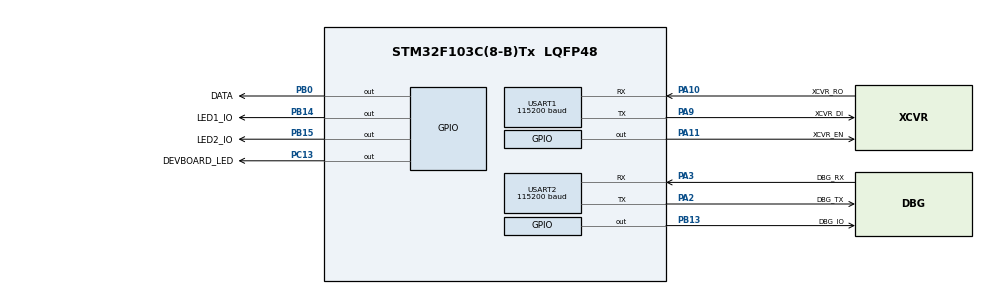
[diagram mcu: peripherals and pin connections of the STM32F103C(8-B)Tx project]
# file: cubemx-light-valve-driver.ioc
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Dma.Request0=USART1_RX
Dma.Request1=USART2_TX
Dma.USART1_RX.0.Direction=DMA_PERIPH_TO_MEMORY
Dma.USART1_RX.0.Instance=DMA1_Channel5
Dma.USART1_RX.0.MemDataAlignment=DMA_MDATAALIGN_BYTE
Dma.USART1_RX.0.MemInc=DMA_MINC_ENABLE
Dma.USART1_RX.0.Mode=DMA_CIRCULAR
Dma.USART1_RX.0.PeriphDataAlignment=DMA_PDATAALIGN_BYTE
Dma.USART1_RX.0.PeriphInc=DMA_PINC_DISABLE
Dma.USART1_RX.0.Priority=DMA_PRIORITY_MEDIUM
Dma.USART2_TX.1.Direction=DMA_MEMORY_TO_PERIPH
Dma.USART2_TX.1.Instance=DMA1_Channel7
Dma.USART2_TX.1.MemDataAlignment=DMA_MDATAALIGN_BYTE
Dma.USART2_TX.1.MemInc=DMA_MINC_ENABLE
Dma.USART2_TX.1.Mode=DMA_NORMAL
Dma.USART2_TX.1.PeriphDataAlignment=DMA_PDATAALIGN_BYTE
Dma.USART2_TX.1.PeriphInc=DMA_PINC_DISABLE
Dma.USART2_TX.1.Priority=DMA_PRIORITY_LOW
FREERTOS.HEAP_NUMBER=4
FREERTOS.INCLUDE_eTaskGetState=1
FREERTOS.INCLUDE_pcTaskGetTaskName=0
FREERTOS.INCLUDE_uxTaskGetStackHighWaterMark=1
FREERTOS.INCLUDE_uxTaskPriorityGet=1
FREERTOS.INCLUDE_vTaskCleanUpResources=0
FREERTOS.INCLUDE_vTaskDelay=1
FREERTOS.INCLUDE_vTaskDelayUntil=1
FREERTOS.INCLUDE_vTaskDelete=1
FREERTOS.INCLUDE_vTaskPrioritySet=1
FREERTOS.INCLUDE_vTaskSuspend=1
FREERTOS.INCLUDE_xEventGroupSetBitFromISR=0
FREERTOS.INCLUDE_xQueueGetMutexHolder=1
FREERTOS.INCLUDE_xSemaphoreGetMutexHolder=0
FREERTOS.INCLUDE_xTaskAbortDelay=0
FREERTOS.INCLUDE_xTaskGetCurrentTaskHandle=0
FREERTOS.INCLUDE_xTaskGetHandle=0
FREERTOS.INCLUDE_xTaskGetSchedulerState=1
FREERTOS.INCLUDE_xTaskResumeFromISR=1
FREERTOS.INCLUDE_xTimerPendFunctionCall=1
FREERTOS.Tasks01=defaultTask,24,256,StartDefaultTask,Default,NULL,Dynamic,NULL,NULL
FREERTOS.configCHECK_FOR_STACK_OVERFLOW=0
FREERTOS.configENABLE_BACKWARD_COMPATIBILITY=1
FREERTOS.configGENERATE_RUN_TIME_STATS=0
FREERTOS.configIDLE_SHOULD_YIELD=1
FREERTOS.configLIBRARY_LOWEST_INTERRUPT_PRIORITY=15
FREERTOS.configLIBRARY_MAX_SYSCALL_INTERRUPT_PRIORITY=5
FREERTOS.configMAX_CO_ROUTINE_PRIORITIES=2
FREERTOS.configMAX_TASK_NAME_LEN=16
FREERTOS.configMINIMAL_STACK_SIZE=128
FREERTOS.configQUEUE_REGISTRY_SIZE=8
FREERTOS.configRECORD_STACK_HIGH_ADDRESS=0
FREERTOS.configTICK_RATE_HZ=1000
FREERTOS.configTIMER_QUEUE_LENGTH=10
FREERTOS.configTIMER_TASK_PRIORITY=2
FREERTOS.configTIMER_TASK_STACK_DEPTH=256
FREERTOS.configTOTAL_HEAP_SIZE=12288
FREERTOS.configUSE_APPLICATION_TASK_TAG=0
FREERTOS.configUSE_COUNTING_SEMAPHORES=1
FREERTOS.configUSE_CO_ROUTINES=0
FREERTOS.configUSE_DAEMON_TASK_STARTUP_HOOK=0
FREERTOS.configUSE_IDLE_HOOK=0
FREERTOS.configUSE_MALLOC_FAILED_HOOK=0
FREERTOS.configUSE_MUTEXES=1
FREERTOS.configUSE_NEWLIB_REENTRANT=0
FREERTOS.configUSE_PREEMPTION=1
FREERTOS.configUSE_RECURSIVE_MUTEXES=1
FREERTOS.configUSE_STATS_FORMATTING_FUNCTIONS=0
FREERTOS.configUSE_TASK_NOTIFICATIONS=1
FREERTOS.configUSE_TICKLESS_IDLE=0
FREERTOS.configUSE_TICK_HOOK=0
FREERTOS.configUSE_TRACE_FACILITY=1
FREERTOS.copyHeapFile=1
Mcu.Family=STM32F1
Mcu.Name=STM32F103C(8-B)Tx
Mcu.Package=LQFP48
NVIC.DMA1_Channel5_IRQn=true\:5\:0\:false\:false\:true\:true\:false\:true\:true
NVIC.DMA1_Channel7_IRQn=true\:5\:0\:false\:false\:true\:true\:false\:true\:true
NVIC.PriorityGroup=NVIC_PRIORITYGROUP_4
NVIC.TIM1_UP_IRQn=true\:8\:0\:true\:false\:true\:true\:true\:true\:true
NVIC.TIM4_IRQn=true\:15\:0\:false\:false\:true\:false\:true\:true\:true
NVIC.TimeBase=TIM4_IRQn
NVIC.TimeBaseIP=TIM4
NVIC.USART1_IRQn=true\:7\:0\:true\:false\:true\:true\:true\:true\:true
NVIC.USART2_IRQn=true\:5\:0\:false\:false\:true\:true\:true\:true\:true
PA10.GPIO_Label=XCVR_RO
PA10.Mode=Asynchronous
PA10.Signal=USART1_RX
PA11.GPIO_Label=XCVR_EN
PA11.Signal=GPIO_Output
PA13.Mode=Serial_Wire
PA13.Signal=SYS_JTMS-SWDIO
PA14.Mode=Serial_Wire
PA14.Signal=SYS_JTCK-SWCLK
PA2.GPIO_Label=DBG_TX
PA2.Mode=Asynchronous
PA2.Signal=USART2_TX
PA3.GPIO_Label=DBG_RX
PA3.Mode=Asynchronous
PA3.Signal=USART2_RX
PA9.GPIO_Label=XCVR_DI
PA9.Mode=Asynchronous
PA9.Signal=USART1_TX
PB0.GPIO_Label=DATA
PB0.GPIO_Speed=GPIO_SPEED_FREQ_HIGH
PB0.Signal=GPIO_Output
PB13.GPIO_Label=DBG_IO
PB13.GPIO_Speed=GPIO_SPEED_FREQ_HIGH
PB13.PinState=GPIO_PIN_RESET
PB13.Signal=GPIO_Output
PB14.GPIO_Label=LED1_IO
PB14.GPIO_ModeDefaultOutputPP=GPIO_MODE_OUTPUT_OD
PB14.GPIO_PuPd=GPIO_NOPULL
PB14.PinState=GPIO_PIN_SET
PB14.Signal=GPIO_Output
PB15.GPIO_Label=LED2_IO
PB15.GPIO_ModeDefaultOutputPP=GPIO_MODE_OUTPUT_OD
PB15.GPIO_PuPd=GPIO_NOPULL
PB15.PinState=GPIO_PIN_SET
PB15.Signal=GPIO_Output
PC13-TAMPER-RTC.GPIO_Label=DEVBOARD_LED
PC13-TAMPER-RTC.Signal=GPIO_Output
ProjectManager.HeapSize=0x200
ProjectManager.StackSize=0x400
ProjectManager.TargetToolchain=Makefile
RCC.AHBFreq_Value=64000000
RCC.APB1CLKDivider=RCC_HCLK_DIV2
RCC.APB1Freq_Value=32000000
RCC.APB1TimFreq_Value=64000000
RCC.APB2Freq_Value=64000000
RCC.APB2TimFreq_Value=64000000
RCC.FLatency=FLASH_LATENCY_2
RCC.HCLKFreq_Value=64000000
RCC.PLLMUL=RCC_PLL_MUL16
RCC.SYSCLKFreq_VALUE=64000000
RCC.SYSCLKSource=RCC_SYSCLKSOURCE_PLLCLK
RCC.USBFreq_Value=64000000
TIM1.Period=360 - 1
USART1.BaudRate=115200
USART1.Mode=MODE_TX_RX
USART1.Parity=PARITY_NONE
USART1.StopBits=STOPBITS_1
USART1.VirtualMode=VM_ASYNC
USART1.WordLength=WORDLENGTH_8B
USART2.BaudRate=115200
USART2.Mode=MODE_TX_RX
USART2.Parity=PARITY_NONE
USART2.StopBits=STOPBITS_1
USART2.VirtualMode=VM_ASYNC
USART2.WordLength=WORDLENGTH_8B
VP_FREERTOS_VS_CMSIS_V2.Mode=CMSIS_V2
VP_SYS_VS_tim4.Mode=TIM4
VP_TIM1_VS_ClockSourceINT.Mode=Internal
board=custom

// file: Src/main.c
/* USER CODE BEGIN Header */
/**
 ******************************************************************************
 * @file           : main.c
 * @brief          : Main program body
 ******************************************************************************
 * @attention
 *
 * Copyright (c) 2022 STMicroelectronics.
 * All rights reserved.
 *
 * This software is licensed under terms that can be found in the LICENSE file
 * in the root directory of this software component.
 * If no LICENSE file comes with this software, it is provided AS-IS.
 *
 ******************************************************************************
 */
/* USER CODE END Header */
#include "main.h"
#include "cmsis_os.h"

/* USER CODE BEGIN Includes */

#include "FreeRTOS.h"
#include "app_main.h"
#include "task.h"

/* USER CODE END Includes */

TIM_HandleTypeDef htim1;

UART_HandleTypeDef huart1;
UART_HandleTypeDef huart2;
DMA_HandleTypeDef hdma_usart1_rx;
DMA_HandleTypeDef hdma_usart2_tx;

/* Definitions for defaultTask */
osThreadId_t defaultTaskHandle;
const osThreadAttr_t defaultTask_attributes = {
  .name = "defaultTask",
  .stack_size = 256 * 4,
  .priority = (osPriority_t) osPriorityNormal,
};

void SystemClock_Config(void);
static void MX_GPIO_Init(void);
static void MX_DMA_Init(void);
static void MX_USART1_UART_Init(void);
static void MX_USART2_UART_Init(void);
static void MX_TIM1_Init(void);
void StartDefaultTask(void *argument);

int main(void)
{

  /* MCU Configuration--------------------------------------------------------*/

  /* Reset of all peripherals, Initializes the Flash interface and the Systick. */
  HAL_Init();

  /* Configure the system clock */
  SystemClock_Config();

  /* Initialize all configured peripherals */
  MX_GPIO_Init();
  MX_DMA_Init();
  MX_USART1_UART_Init();
  MX_USART2_UART_Init();
  MX_TIM1_Init();

  /* Init scheduler */
  osKernelInitialize();

  /* Create the thread(s) */
  /* creation of defaultTask */
  defaultTaskHandle = osThreadNew(StartDefaultTask, NULL, &defaultTask_attributes);

  /* USER CODE BEGIN RTOS_EVENTS */
    /* add events, ... */
    // vTaskStartScheduler();
  /* USER CODE END RTOS_EVENTS */

  /* Start scheduler */
  osKernelStart();

  /* We should never get here as control is now taken by the scheduler */
  /* Infinite loop */
    while (1) {

    }
}

void SystemClock_Config(void)
{
  LL_FLASH_SetLatency(LL_FLASH_LATENCY_2);
  while(LL_FLASH_GetLatency()!= LL_FLASH_LATENCY_2)
  {
  }
  LL_RCC_HSI_SetCalibTrimming(16);
  LL_RCC_HSI_Enable();

   /* Wait till HSI is ready */
  while(LL_RCC_HSI_IsReady() != 1)
  {

  }
  LL_RCC_PLL_ConfigDomain_SYS(LL_RCC_PLLSOURCE_HSI_DIV_2, LL_RCC_PLL_MUL_16);
  LL_RCC_PLL_Enable();

   /* Wait till PLL is ready */
  while(LL_RCC_PLL_IsReady() != 1)
  {

  }
  LL_RCC_SetAHBPrescaler(LL_RCC_SYSCLK_DIV_1);
  LL_RCC_SetAPB1Prescaler(LL_RCC_APB1_DIV_2);
  LL_RCC_SetAPB2Prescaler(LL_RCC_APB2_DIV_1);
  LL_RCC_SetSysClkSource(LL_RCC_SYS_CLKSOURCE_PLL);

   /* Wait till System clock is ready */
  while(LL_RCC_GetSysClkSource() != LL_RCC_SYS_CLKSOURCE_STATUS_PLL)
  {

  }
  LL_SetSystemCoreClock(64000000);

   /* Update the time base */
  if (HAL_InitTick (TICK_INT_PRIORITY) != HAL_OK)
  {
    Error_Handler();
  }
}

static void MX_TIM1_Init(void)
{

  TIM_ClockConfigTypeDef sClockSourceConfig = {0};
  TIM_MasterConfigTypeDef sMasterConfig = {0};

  htim1.Instance = TIM1;
  htim1.Init.Prescaler = 0;
  htim1.Init.CounterMode = TIM_COUNTERMODE_UP;
  htim1.Init.Period = 360 - 1;
  htim1.Init.ClockDivision = TIM_CLOCKDIVISION_DIV1;
  htim1.Init.RepetitionCounter = 0;
  htim1.Init.AutoReloadPreload = TIM_AUTORELOAD_PRELOAD_DISABLE;
  if (HAL_TIM_Base_Init(&htim1) != HAL_OK)
  {
    Error_Handler();
  }
  sClockSourceConfig.ClockSource = TIM_CLOCKSOURCE_INTERNAL;
  if (HAL_TIM_ConfigClockSource(&htim1, &sClockSourceConfig) != HAL_OK)
  {
    Error_Handler();
  }
  sMasterConfig.MasterOutputTrigger = TIM_TRGO_RESET;
  sMasterConfig.MasterSlaveMode = TIM_MASTERSLAVEMODE_DISABLE;
  if (HAL_TIMEx_MasterConfigSynchronization(&htim1, &sMasterConfig) != HAL_OK)
  {
    Error_Handler();
  }

}

static void MX_USART1_UART_Init(void)
{

  huart1.Instance = USART1;
  huart1.Init.BaudRate = 115200;
  huart1.Init.WordLength = UART_WORDLENGTH_8B;
  huart1.Init.StopBits = UART_STOPBITS_1;
  huart1.Init.Parity = UART_PARITY_NONE;
  huart1.Init.Mode = UART_MODE_TX_RX;
  huart1.Init.HwFlowCtl = UART_HWCONTROL_NONE;
  huart1.Init.OverSampling = UART_OVERSAMPLING_16;
  if (HAL_UART_Init(&huart1) != HAL_OK)
  {
    Error_Handler();
  }

}

static void MX_USART2_UART_Init(void)
{

  huart2.Instance = USART2;
  huart2.Init.BaudRate = 115200;
  huart2.Init.WordLength = UART_WORDLENGTH_8B;
  huart2.Init.StopBits = UART_STOPBITS_1;
  huart2.Init.Parity = UART_PARITY_NONE;
  huart2.Init.Mode = UART_MODE_TX_RX;
  huart2.Init.HwFlowCtl = UART_HWCONTROL_NONE;
  huart2.Init.OverSampling = UART_OVERSAMPLING_16;
  if (HAL_UART_Init(&huart2) != HAL_OK)
  {
    Error_Handler();
  }

}

static void MX_DMA_Init(void)
{

  /* DMA controller clock enable */
  __HAL_RCC_DMA1_CLK_ENABLE();

  /* DMA interrupt init */
  /* DMA1_Channel5_IRQn interrupt configuration */
  HAL_NVIC_SetPriority(DMA1_Channel5_IRQn, 5, 0);
  HAL_NVIC_EnableIRQ(DMA1_Channel5_IRQn);
  /* DMA1_Channel7_IRQn interrupt configuration */
  HAL_NVIC_SetPriority(DMA1_Channel7_IRQn, 5, 0);
  HAL_NVIC_EnableIRQ(DMA1_Channel7_IRQn);

}

static void MX_GPIO_Init(void)
{
  LL_GPIO_InitTypeDef GPIO_InitStruct = {0};

  /* GPIO Ports Clock Enable */
  LL_APB2_GRP1_EnableClock(LL_APB2_GRP1_PERIPH_GPIOC);
  LL_APB2_GRP1_EnableClock(LL_APB2_GRP1_PERIPH_GPIOA);
  LL_APB2_GRP1_EnableClock(LL_APB2_GRP1_PERIPH_GPIOB);

  /**/
  LL_GPIO_ResetOutputPin(DEVBOARD_LED_GPIO_Port, DEVBOARD_LED_Pin);

  /**/
  LL_GPIO_ResetOutputPin(GPIOB, DATA_Pin|DBG_IO_Pin);

  /**/
  LL_GPIO_ResetOutputPin(XCVR_EN_GPIO_Port, XCVR_EN_Pin);

  /**/
  LL_GPIO_SetOutputPin(GPIOB, LED1_IO_Pin|LED2_IO_Pin);

  /**/
  GPIO_InitStruct.Pin = DEVBOARD_LED_Pin;
  GPIO_InitStruct.Mode = LL_GPIO_MODE_OUTPUT;
  GPIO_InitStruct.Speed = LL_GPIO_SPEED_FREQ_LOW;
  GPIO_InitStruct.OutputType = LL_GPIO_OUTPUT_PUSHPULL;
  LL_GPIO_Init(DEVBOARD_LED_GPIO_Port, &GPIO_InitStruct);

  /**/
  GPIO_InitStruct.Pin = DATA_Pin|DBG_IO_Pin;
  GPIO_InitStruct.Mode = LL_GPIO_MODE_OUTPUT;
  GPIO_InitStruct.Speed = LL_GPIO_SPEED_FREQ_HIGH;
  GPIO_InitStruct.OutputType = LL_GPIO_OUTPUT_PUSHPULL;
  LL_GPIO_Init(GPIOB, &GPIO_InitStruct);

  /**/
  GPIO_InitStruct.Pin = LED1_IO_Pin|LED2_IO_Pin;
  GPIO_InitStruct.Mode = LL_GPIO_MODE_OUTPUT;
  GPIO_InitStruct.Speed = LL_GPIO_SPEED_FREQ_LOW;
  GPIO_InitStruct.OutputType = LL_GPIO_OUTPUT_OPENDRAIN;
  LL_GPIO_Init(GPIOB, &GPIO_InitStruct);

  /**/
  GPIO_InitStruct.Pin = XCVR_EN_Pin;
  GPIO_InitStruct.Mode = LL_GPIO_MODE_OUTPUT;
  GPIO_InitStruct.Speed = LL_GPIO_SPEED_FREQ_LOW;
  GPIO_InitStruct.OutputType = LL_GPIO_OUTPUT_PUSHPULL;
  LL_GPIO_Init(XCVR_EN_GPIO_Port, &GPIO_InitStruct);

}

void StartDefaultTask(void *argument)
{
  /* USER CODE BEGIN 5 */
    app_main();
    osThreadTerminate(defaultTaskHandle);

    /* Infinite loop */
    // for (;;) {
    //     osDelay(1);
    // }
  /* USER CODE END 5 */
}

void HAL_TIM_PeriodElapsedCallback(TIM_HandleTypeDef *htim)
{
  if (htim->Instance == TIM4) {
    HAL_IncTick();
  }
}

void Error_Handler(void)
{
    __disable_irq();
    while (1) {
    }
}
